# S32K324_M7 register map
Vendor: NXP Semiconductors; File version: 1.1
CPU: CM7 r0p1, little endian, MPU, FPU, VTOR, 4 interrupt priority bits
Registers are 32-bit, read-write, reset 0x0 unless marked. A register's access mark holds for its fields unless they carry their own. Offsets are from the block's base; [hi:lo] are bit positions; {n}, {i} and the like mark numbered series; 'fields as' and 'values as' point back to an identical list.

## MC_ME
Base 0x402DC000
0x00 CTL_KEY reset 0x5AF0 — Control Key Register
  [15:0] KEY — Control key
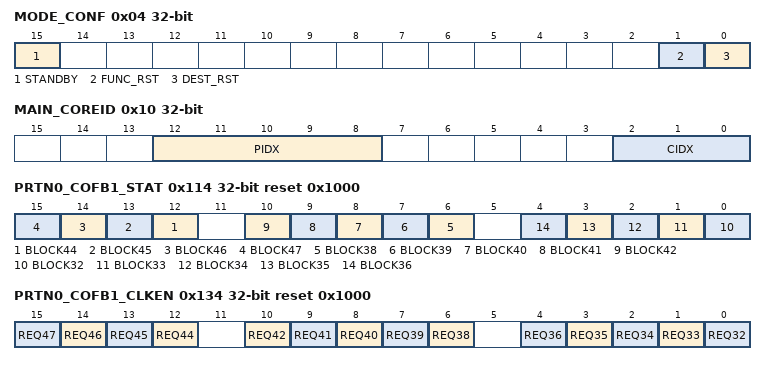
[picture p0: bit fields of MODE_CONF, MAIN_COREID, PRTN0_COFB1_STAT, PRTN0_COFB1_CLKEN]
0x04 MODE_CONF — Mode Configuration Register
  [15] STANDBY — Standby request
  [1] FUNC_RST — Functional reset request
  [0] DEST_RST — Destructive reset request
0x08 MODE_UPD — Mode Update Register
  [0] MODE_UPD — Mode update
0x0C MODE_STAT ro — Mode Status Register
  [0] PREV_MODE — Previous mode
    0=RESET (The previous mode was reset (any reset).); 1=STANDBY (The previous mode was standby.)
0x10 MAIN_COREID
  [12:8] PIDX — Partition index
  [2:0] CIDX — Core index
{0x100+0x200*i} PRTN{i}_PCONF reset 0x1 (i=0..2) — Partition {i} Process Configuration Register
  [0] PCE — Partition clock enable
    0=DISABLE (Disable the clock to IPs); 1=ENABLE (Enable the clock to IPs)
{0x104+0x200*i} PRTN{i}_PUPD (i=0..2) — Partition {i} Process Update Register
  [0] PCUD — Partition clock update
    0=NO_TRIGGER (Do not trigger the hardware process); 1=TRIGGER (Trigger the hardware process)
{0x108+0x200*i} PRTN{i}_STAT ro reset 0x1 (i=0..2) — Partition {i} Status Register
  [0] PCS — Partition clock status
    0=INACTIVE (Clock is inactive); 1=ACTIVE (Clock is active)
0x114 PRTN0_COFB1_STAT ro reset 0x1000 — Partition 0 COFB Set 1 Clock Status Register
  [all] fields
    0=CLOCK_DISABLE (Clock is not running.); 1=CLOCK_ENABLE (Clock is running.)
  [n-32] BLOCK{n} (n=44..47) — IP block status
  [n-32] BLOCK{n} (n=38..42) — IP block status
  [n-32] BLOCK{n} (n=32..36) — IP block status
0x134 PRTN0_COFB1_CLKEN reset 0x1000 — Partition 0 COFB Set 1 Clock Enable Register
  [all] fields
    0=OFF (Clock is turned off.); 1=ON (Clock is turned on.)
  [n-32] REQ{n} (n=44..47) — Clock enable
  [n-32] REQ{n} (n=38..42) — Clock enable
  [n-32] REQ{n} (n=32..36) — Clock enable
0x140 PRTN0_CORE0_PCONF — Partition 0 Core 0 Process Configuration Register
  [0] CCE — Core 0 clock enable
    0=DISABLE (Disable the core clock); 1=ENABLE (Enable the core clock)
0x144 PRTN0_CORE0_PUPD — Partition 0 Core 0 Process Update Register
  [0] CCUPD — Core 0 clock update
    0=DISABLE (Do not trigger the hardware process); 1=ENABLE (Trigger the hardware process)
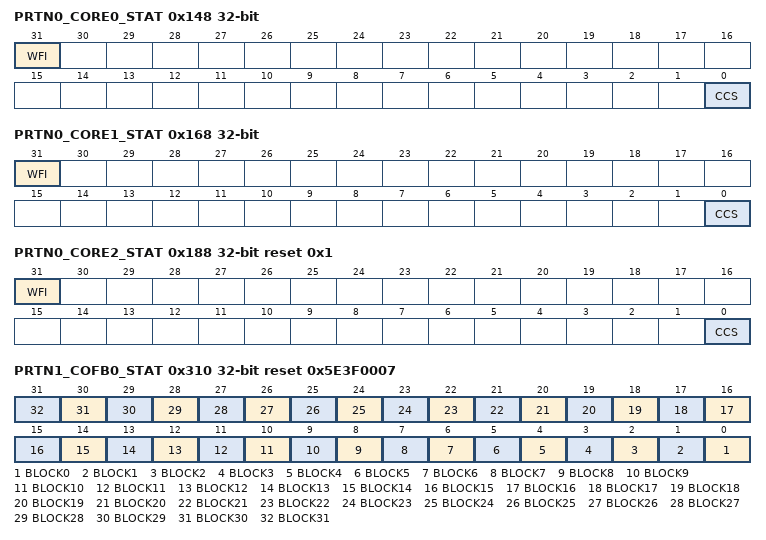
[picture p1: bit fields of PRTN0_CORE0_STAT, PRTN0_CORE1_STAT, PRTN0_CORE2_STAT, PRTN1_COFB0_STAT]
0x148 PRTN0_CORE0_STAT ro — Partition 0 Core 0 Status Register
  [31] WFI — Wait for interrupt status
    0=NO_WFI (No WFI executed); 1=WFI (WFI executed)
  [0] CCS — Core 0 clock process status
    0=INACTIVE (Clock is inactive.); 1=ACTIVE (Clock is active.)
0x14C PRTN0_CORE0_ADDR reset 0x400000 — Partition 0 Core 0 Address Register
  [31:2] ADDR — Address
0x160 PRTN0_CORE1_PCONF — Partition 0 Core 1 Process Configuration Register
  [0] CCE — Core 1 clock enable
    values as PRTN0_CORE0_PCONF.CCE
0x164 PRTN0_CORE1_PUPD — Partition 0 Core 1 Process Update Register
  [0] CCUPD — Core 1 clock update
    values as PRTN0_CORE0_PUPD.CCUPD
0x168 PRTN0_CORE1_STAT ro — Partition 0 Core 1 Status Register
  [31] WFI — Wait for interrupt status
    0=NO_WFI (No WFI executed); 1=WFI (WFI executed)
  [0] CCS — Core 1 clock process status
    0=INACTIVE (Clock is inactive.); 1=ACTIVE (Clock is active.)
0x16C PRTN0_CORE1_ADDR reset 0x410000 — Partition 0 Core 1 Address Register
  [31:2] ADDR — Address
0x188 PRTN0_CORE2_STAT ro reset 0x1 — Partition 0 Core 2 Status Register
  [31] WFI — Wait for interrupt status
    0=NO_WFI (No WFI executed); 1=WFI (WFI executed)
  [0] CCS — Core 2 clock process status
    1=ACTIVE (Clock is active.)
0x18C PRTN0_CORE2_ADDR ro reset 0x7FFC00 — Partition 0 Core 2 Address Register
  [31:2] ADDR — Address
0x310 PRTN1_COFB0_STAT ro reset 0x5E3F0007 — Partition 1 COFB Set 0 Clock Status Register
  [all] fields
    values as the fields of PRTN0_COFB1_STAT
  [n] BLOCK{n} (n=0..31) — IP block status
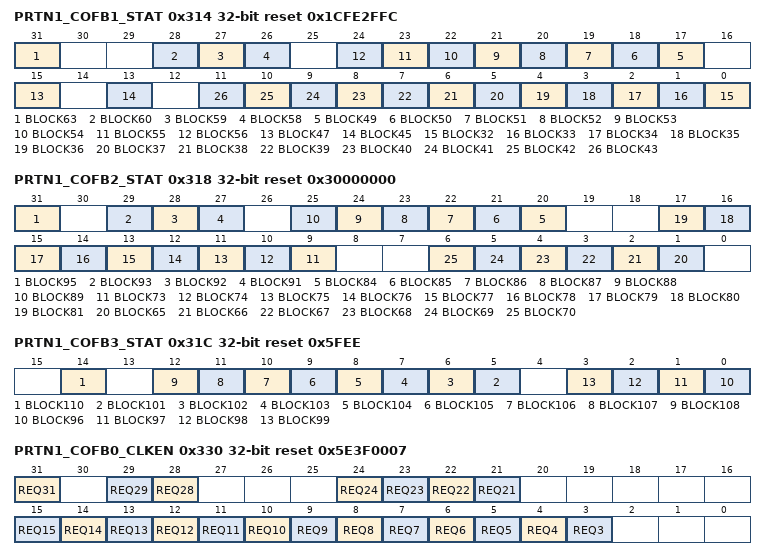
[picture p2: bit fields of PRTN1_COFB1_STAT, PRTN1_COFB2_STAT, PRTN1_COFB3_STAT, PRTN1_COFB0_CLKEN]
0x314 PRTN1_COFB1_STAT ro reset 0x1CFE2FFC — Partition 1 COFB Set 1 Clock Status Register
  [all] fields
    values as the fields of PRTN0_COFB1_STAT
  [31] BLOCK63 — IP block status
  [28] BLOCK60 — IP block status
  [27] BLOCK59 — IP block status
  [26] BLOCK58 — IP block status
  [n-32] BLOCK{n} (n=49..56) — IP block status
  [15] BLOCK47 — IP block status
  [13] BLOCK45 — IP block status
  [n-32] BLOCK{n} (n=32..43) — IP block status
0x318 PRTN1_COFB2_STAT ro reset 0x30000000 — Partition 1 COFB Set 2 Clock Status Register
  [all] fields
    values as the fields of PRTN0_COFB1_STAT
  [31] BLOCK95 — IP block status
  [29] BLOCK93 — IP block status
  [28] BLOCK92 — IP block status
  [27] BLOCK91 — IP block status
  [n-64] BLOCK{n} (n=84..89) — IP block status
  [n-64] BLOCK{n} (n=73..81) — IP block status
  [n-64] BLOCK{n} (n=65..70) — IP block status
0x31C PRTN1_COFB3_STAT ro reset 0x5FEE — Partition 1 COFB Set 3 Clock Status Register
  [all] fields
    values as the fields of PRTN0_COFB1_STAT
  [14] BLOCK110 — IP block status
  [n-96] BLOCK{n} (n=101..108) — IP block status
  [n-96] BLOCK{n} (n=96..99) — IP block status
0x330 PRTN1_COFB0_CLKEN reset 0x5E3F0007 — Partition 1 COFB Set 0 Clock Enable Register
  [all] fields
    0=OFF (Clock is turned off.); 1=ON (Clock is turned on.)
  [31] REQ31 — Clock enable
  [29] REQ29 — Clock enable
  [28] REQ28 — Clock enable
  [n] REQ{n} (n=21..24) — Clock enable
  [n] REQ{n} (n=3..15) — Clock enable
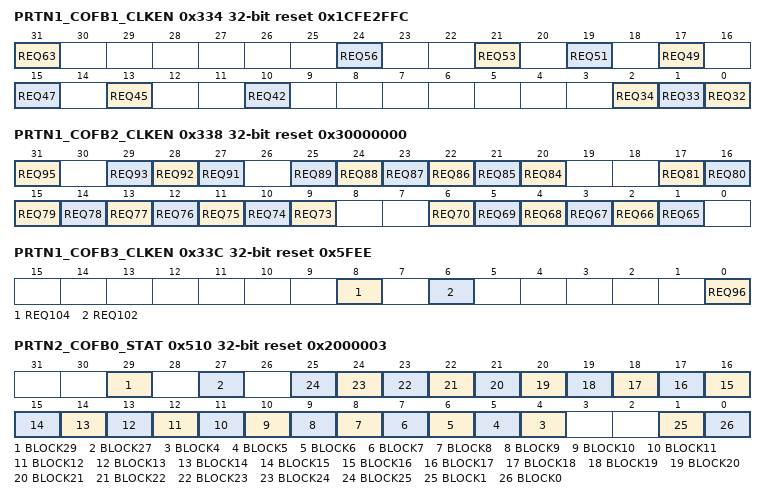
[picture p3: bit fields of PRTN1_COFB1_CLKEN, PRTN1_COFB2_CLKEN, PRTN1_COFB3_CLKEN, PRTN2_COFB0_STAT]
0x334 PRTN1_COFB1_CLKEN reset 0x1CFE2FFC — Partition 1 COFB Set 1 Clock Enable Register
  [all] fields
    0=OFF (Clock is turned off.); 1=ON (Clock is turned on.)
  [31] REQ63 — Clock enable
  [24] REQ56 — Clock enable
  [21] REQ53 — Clock enable
  [19] REQ51 — Clock enable
  [17] REQ49 — Clock enable
  [15] REQ47 — Clock enable
  [13] REQ45 — Clock enable
  [10] REQ42 — Clock enable
  [2] REQ34 — Clock enable
  [1] REQ33 — Clock enable
  [0] REQ32 — Clock enable
0x338 PRTN1_COFB2_CLKEN reset 0x30000000 — Partition 1 COFB Set 2 Clock Enable Register
  [all] fields
    0=OFF (Clock is turned off.); 1=ON (Clock is turned on.)
  [31] REQ95 — Clock enable
  [29] REQ93 — Clock enable
  [28] REQ92 — Clock enable
  [27] REQ91 — Clock enable
  [n-64] REQ{n} (n=84..89) — Clock enable
  [n-64] REQ{n} (n=73..81) — Clock enable
  [n-64] REQ{n} (n=65..70) — Clock enable
0x33C PRTN1_COFB3_CLKEN reset 0x5FEE — Partition 1 COFB Set 3 Clock Enable Register
  [all] fields
    0=OFF (Clock is turned off.); 1=ON (Clock is turned on.)
  [8] REQ104 — Clock enable
  [6] REQ102 — Clock enable
  [0] REQ96 — Clock enable
0x510 PRTN2_COFB0_STAT ro reset 0x2000003 — Partition 2 COFB Set 0 Clock Status Register
  [all] fields
    values as the fields of PRTN0_COFB1_STAT
  [29] BLOCK29 — IP block status
  [27] BLOCK27 — IP block status
  [n] BLOCK{n} (n=4..25) — IP block status
  [1] BLOCK1 — IP block status
  [0] BLOCK0 — IP block status
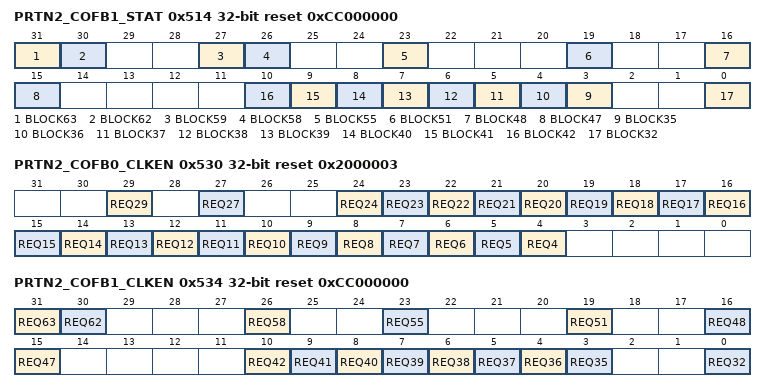
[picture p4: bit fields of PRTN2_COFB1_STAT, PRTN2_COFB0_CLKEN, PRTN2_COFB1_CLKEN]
0x514 PRTN2_COFB1_STAT ro reset 0xCC000000 — Partition 2 COFB Set 1 Clock Status Register
  [all] fields
    values as the fields of PRTN0_COFB1_STAT
  [31] BLOCK63 — IP block status
  [30] BLOCK62 — IP block status
  [27] BLOCK59 — IP block status
  [26] BLOCK58 — IP block status
  [23] BLOCK55 — IP block status
  [19] BLOCK51 — IP block status
  [16] BLOCK48 — IP block status
  [15] BLOCK47 — IP block status
  [n-32] BLOCK{n} (n=35..42) — IP block status
  [0] BLOCK32 — IP block status
0x530 PRTN2_COFB0_CLKEN reset 0x2000003 — Partition 2 COFB Set 0 Clock Enable Register
  [all] fields
    0=OFF (Clock is turned off.); 1=ON (Clock is turned on.)
  [29] REQ29 — Clock enable
  [27] REQ27 — Clock enable
  [n] REQ{n} (n=4..24) — Clock enable
0x534 PRTN2_COFB1_CLKEN reset 0xCC000000 — Partition 2 COFB Set 1 Clock Enable Register
  [all] fields
    0=OFF (Clock is turned off.); 1=ON (Clock is turned on.)
  [31] REQ63 — Clock enable
  [30] REQ62 — Clock enable
  [26] REQ58 — Clock enable
  [23] REQ55 — Clock enable
  [19] REQ51 — Clock enable
  [16] REQ48 — Clock enable
  [15] REQ47 — Clock enable
  [n-32] REQ{n} (n=35..42) — Clock enable
  [0] REQ32 — Clock enable
